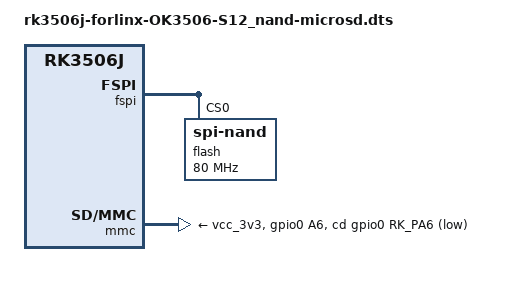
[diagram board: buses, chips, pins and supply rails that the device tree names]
// SPDX-License-Identifier: (GPL-2.0+ OR MIT)
/*
 * Copyright (c) 2024 Rockchip Electronics Co., Ltd.
 */

/dts-v1/;

#include "rk3506j-forlinx-OK3506-S12.dtsi"

/ {
	chosen {
		bootargs = "earlyprintk earlycon=uart8250,mmio32,0xff0a0000,1500000n8 console=ttyFIQ0";
	};
};

&fspi {
	status = "okay";

	flash@0 {
		compatible = "spi-nand";
		reg = <0>;
		spi-max-frequency = <80000000>;
		spi-rx-bus-width = <4>;
		spi-tx-bus-width = <1>;
	};
};

&mmc {
	no-sdio;
	no-mmc;
	cap-sd-highspeed;
	cd-gpios = <&gpio0 RK_PA6 GPIO_ACTIVE_LOW>;
	disable-wp;
	pinctrl-names = "default";
	pinctrl-0 = <&sdmmc_clk_pins &sdmmc_cmd_pins &sdmmc_bus4_pins &sdmmc_det>;
	vqmmc-supply = <&vcc_3v3>;
	vmmc-supply = <&vcc_3v3>;
	status = "okay";
};

&pinctrl {
	sdmmc {
		sdmmc_det: sdmmc-det {
			rockchip,pins = <0 RK_PA6 RK_FUNC_GPIO &pcfg_pull_up>;
		};
	};
};
